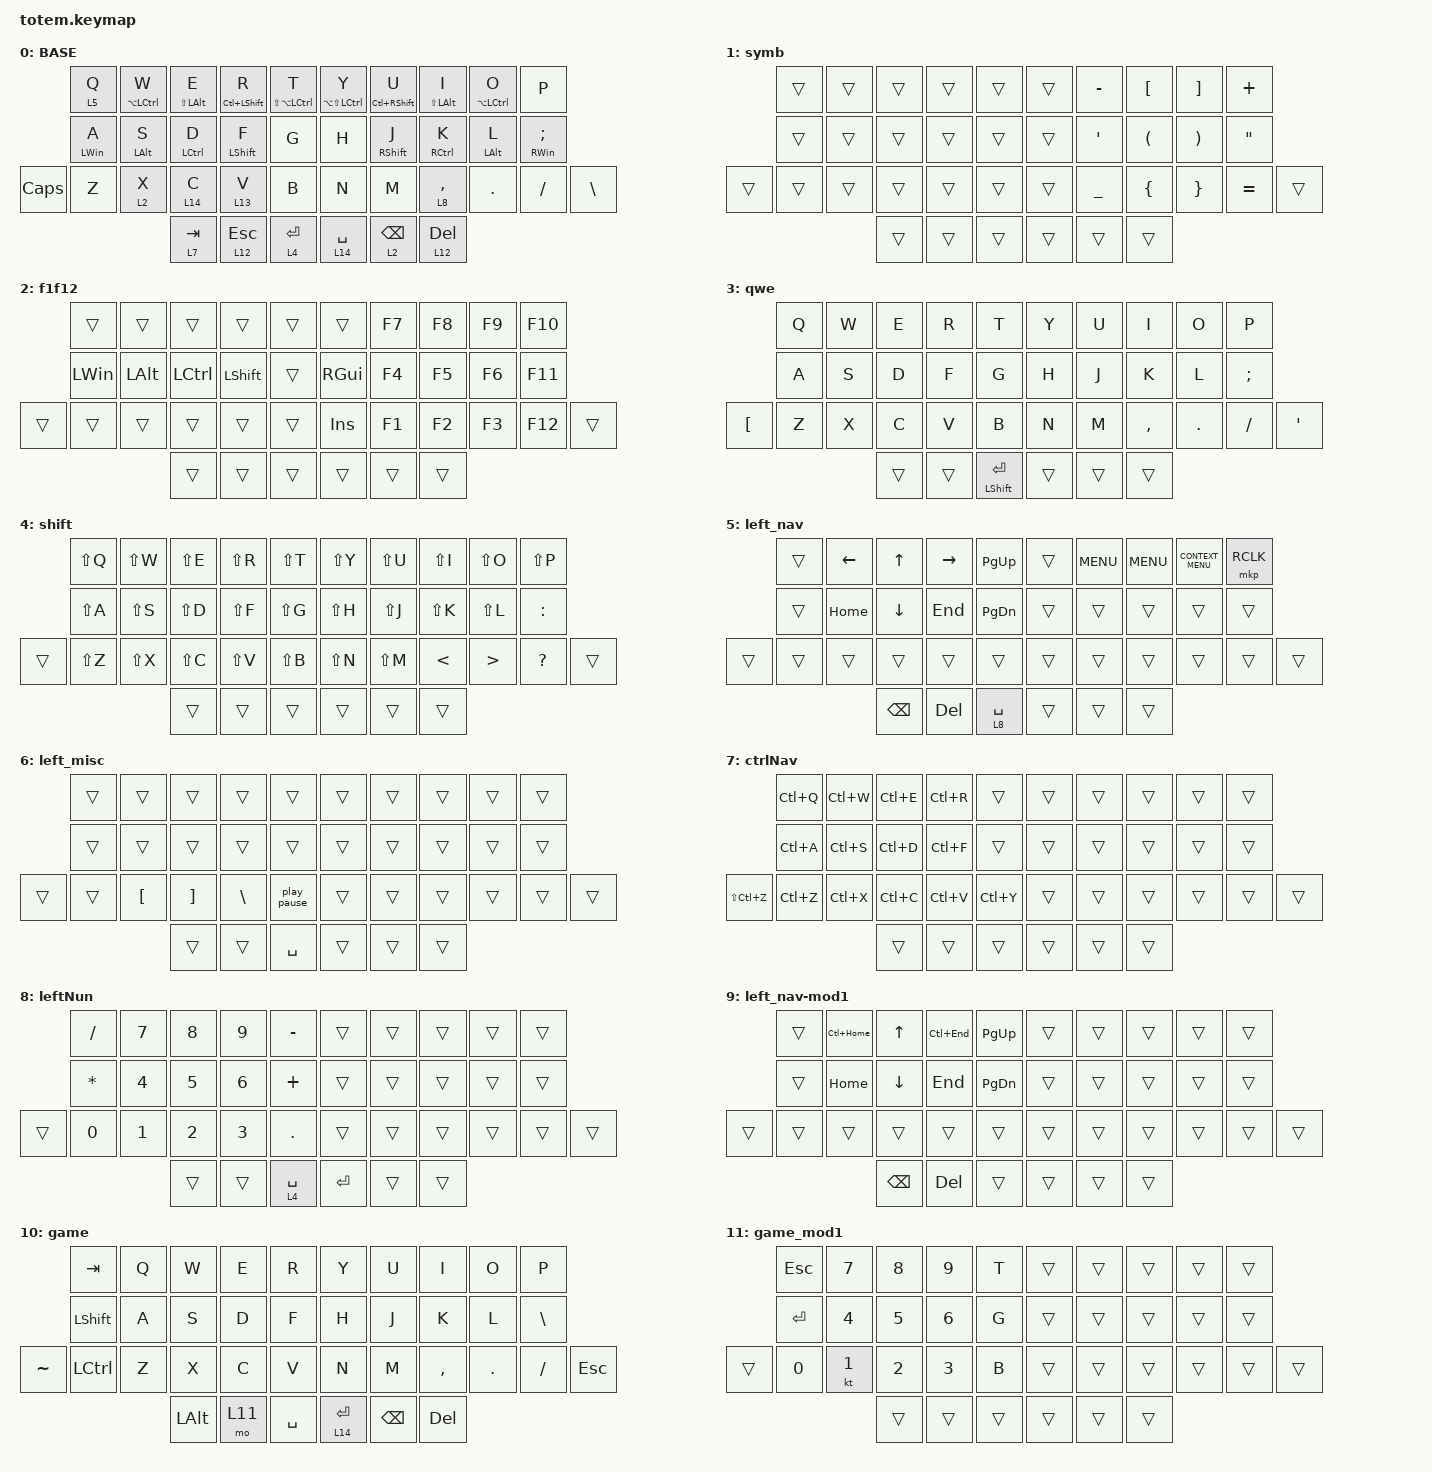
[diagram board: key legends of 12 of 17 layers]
//
//                                                        ▀▀▀▀▀     ▀▀▀▀▀          ▀▀█▀▀
//                                                        ▄▀▀▀▄  ▄  ▄▀▀▀▄  ▄  ▄▀▀▀▄  █  ▄▀▀▀▄
//                                                        █   █  █  █   █  █  █   █  █  █   █
//                                                         ▀▀▀   █   ▀▀▀   █   ▀▀▀   ▀   ▀▀▀
//                                                               █      ▄▄▄█▄▄▄    █   █  
//                                                               ▀      █  █  █     █▄█
//                                                             ▀▀▀▀▀    █  █  █      ▀
//                                                                      ▀  ▀  ▀
//
// ▄▄▄▄▄▄▄▄▄▄▄▄▄▄▄▄▄▄▄▄▄▄▄▄▄▄▄▄▄▄▄▄▄▄▄▄▄▄▄▄▄▄▄▄▄▄▄▄▄▄▄▄▄▄▄▄▄▄▄▄▄▄▄▄▄▄▄▄▄▄▄▄▄▄▄▄▄▄▄▄▄▄▄▄▄▄▄▄▄▄▄▄▄▄▄▄▄▄▄▄▄▄▄▄▄▄▄▄▄▄▄▄▄▄▄▄▄▄▄▄▄▄▄▄▄▄▄▄▄▄▄▄▄▄▄▄▄▄▄▄▄▄▄▄▄▄▄▄▄

#include <dt-bindings/zmk/mouse.h>
#include <behaviors.dtsi>
#include <dt-bindings/zmk/bt.h>
#include <dt-bindings/zmk/keys.h>
#include <dt-bindings/zmk/pointing.h>

#define BASE 0
#define NAV  1
#define SYM  2
#define ADJ  3
#define TVP1 4
#define TVP2 5

&mt {
    quick-tap-ms = <100>;
    global-quick-tap;
    flavor = "tap-preferred";
    tapping-term-ms = <170>;
};

/ {
    combos {
        compatible = "zmk,combos";

        rus {
            bindings = <&rus>;
            key-positions = <20 31>;
            layers = <0>;
            timeout-ms = <75>;
            require-prior-idle-ms = <200>;
        };

        eng {
            bindings = <&eng>;
            key-positions = <20 31>;
            layers = <3>;
            timeout-ms = <75>;
            require-prior-idle-ms = <200>;
        };

        LeftBracket {
            bindings = <&kp LEFT_BRACKET>;
            key-positions = <2 3>;
            layers = <0 4 3>;
            timeout-ms = <75>;
            require-prior-idle-ms = <75>;
        };

        RightBracket {
            bindings = <&kp RIGHT_BRACKET>;
            key-positions = <6 7>;
            layers = <0 4 3>;
            timeout-ms = <75>;
            require-prior-idle-ms = <75>;
        };

        LeftParenthesis {
            bindings = <&kp LEFT_PARENTHESIS>;
            key-positions = <12 13>;
            layers = <0 4 3>;
            timeout-ms = <75>;
            require-prior-idle-ms = <75>;
        };

        RightParenthesis {
            bindings = <&kp RIGHT_PARENTHESIS>;
            key-positions = <16 17>;
            layers = <0 4 3>;
            timeout-ms = <75>;
            require-prior-idle-ms = <75>;
        };

        LeftBrace {
            bindings = <&kp LEFT_BRACE>;
            key-positions = <23 24>;
            layers = <0 4 3>;
            timeout-ms = <75>;
            require-prior-idle-ms = <75>;
        };

        RightBrace {
            bindings = <&kp RIGHT_BRACE>;
            key-positions = <27 28>;
            layers = <0 4 3>;
            timeout-ms = <75>;
            require-prior-idle-ms = <75>;
        };

        Minus {
            bindings = <&kp MINUS>;
            key-positions = <1 2>;
            layers = <0 4 3>;
            timeout-ms = <75>;
            require-prior-idle-ms = <75>;
        };

        Plus {
            bindings = <&kp PLUS>;
            key-positions = <7 8>;
            layers = <0 4 3>;
            timeout-ms = <75>;
            require-prior-idle-ms = <75>;
        };

        Underscore {
            bindings = <&kp UNDER>;
            key-positions = <22 23>;
            layers = <0 4 3>;
            timeout-ms = <75>;
            require-prior-idle-ms = <75>;
        };

        Equal {
            bindings = <&kp EQUAL>;
            key-positions = <28 29>;
            layers = <0 4 3>;
            timeout-ms = <75>;
            require-prior-idle-ms = <75>;
        };

        Quote {
            bindings = <&kp EXCLAMATION>;
            key-positions = <16 18>;
            layers = <0 4 3>;
            timeout-ms = <75>;
            require-prior-idle-ms = <75>;
        };

        QuoteDouble {
            bindings = <&kp QUESTION>;
            key-positions = <13 11>;
            layers = <0 4 3>;
            timeout-ms = <75>;
            require-prior-idle-ms = <75>;
        };

        QuestionMark {
            bindings = <&kp QUESTION>;
            key-positions = <1 3>;
            layers = <0 4 3>;
            timeout-ms = <75>;
            require-prior-idle-ms = <75>;
        };

        Exclamation {
            bindings = <&kp EXCLAMATION>;
            key-positions = <6 8>;
            layers = <0 4 3>;
            timeout-ms = <75>;
            require-prior-idle-ms = <75>;
        };

        Percent {
            bindings = <&kp PERCENT>;
            key-positions = <22 24>;
            layers = <0 4 3>;
            timeout-ms = <75>;
            require-prior-idle-ms = <75>;
        };

        Asterisk {
            bindings = <&kp ASTERISK>;
            key-positions = <27 29>;
            layers = <0 4 3>;
            timeout-ms = <75>;
            require-prior-idle-ms = <75>;
        };

        Grave {
            bindings = <&kp GRAVE>;
            key-positions = <13 11 12>;
            layers = <0 4 3>;
            timeout-ms = <75>;
            require-prior-idle-ms = <75>;
        };

        Tilde {
            bindings = <&kp TILDE>;
            key-positions = <16 17 18>;
            layers = <0 4 3>;
            timeout-ms = <75>;
            require-prior-idle-ms = <75>;
        };

        AtSign {
            bindings = <&kp AT>;
            key-positions = <3 1 2>;
            layers = <0 4 3>;
            timeout-ms = <75>;
            require-prior-idle-ms = <75>;
        };

        Caret {
            bindings = <&kp CARET>;
            key-positions = <6 7 8>;
            layers = <0 4 3>;
            timeout-ms = <75>;
            require-prior-idle-ms = <75>;
        };

        Hash {
            bindings = <&kp HASH>;
            key-positions = <11 23>;
            layers = <0 4 3>;
            timeout-ms = <75>;
            require-prior-idle-ms = <75>;
        };

        Dollar {
            bindings = <&kp DOLLAR>;
            key-positions = <28 18>;
            layers = <0 4 3>;
            timeout-ms = <75>;
            require-prior-idle-ms = <75>;
        };

        Pipe {
            bindings = <&kp PIPE>;
            key-positions = <23 13>;
            layers = <0 4>;
            timeout-ms = <75>;
            require-prior-idle-ms = <75>;
        };

        Ampersand {
            bindings = <&kp AMPERSAND>;
            key-positions = <16 28>;
            layers = <0 4>;
            timeout-ms = <75>;
            require-prior-idle-ms = <75>;
        };

        Backslash2 {
            bindings = <&kp BACKSLASH>;
            key-positions = <1 12 13>;
            layers = <0 4 3>;
            timeout-ms = <75>;
            require-prior-idle-ms = <75>;
        };

        Backslash {
            bindings = <&kp SQT>;
            key-positions = <11 12>;
            layers = <0 4 3>;
            require-prior-idle-ms = <75>;
            timeout-ms = <75>;
        };

        Slash {
            bindings = <&kp DOUBLE_QUOTES>;
            key-positions = <17 18>;
            layers = <0 4 3>;
            require-prior-idle-ms = <75>;
            timeout-ms = <75>;
        };

        endDel {
            bindings = <&endDel>;
            key-positions = <21 22>;
            layers = <0 4>;
            timeout-ms = <75>;
            require-prior-idle-ms = <200>;
        };

        homeBackspace {
            bindings = <&homeBackspace>;
            key-positions = <30 29>;
            layers = <0 4>;
            timeout-ms = <75>;
            require-prior-idle-ms = <200>;
        };

        homeEndDel {
            bindings = <&homeEndDel>;
            key-positions = <11 12 17 18>;
            layers = <0>;
            timeout-ms = <75>;
            require-prior-idle-ms = <200>;
        };

        tab {
            bindings = <&kp TAB>;
            key-positions = <10 11>;
            layers = <0>;
            timeout-ms = <75>;
            require-prior-idle-ms = <200>;
        };

        caps {
            bindings = <&caps_word>;
            key-positions = <18 19>;
            layers = <0>;
            timeout-ms = <75>;
            require-prior-idle-ms = <200>;
        };

        bootloaderL {
            bindings = <&bootloader>;
            key-positions = <20 4>;
            timeout-ms = <75>;
            require-prior-idle-ms = <200>;
        };

        bootloaderR {
            bindings = <&bootloader>;
            key-positions = <31 5>;
            timeout-ms = <75>;
            require-prior-idle-ms = <200>;
        };

        releaseMods {
            bindings = <&release_mod>;
            key-positions = <2 7>;
            timeout-ms = <75>;
            require-prior-idle-ms = <200>;
        };

        toggleNav {
            bindings = <&tog 14>;
            key-positions = <35 17>;
            layers = <0 14>;
            timeout-ms = <75>;
            require-prior-idle-ms = <200>;
        };

        toggleNum {
            bindings = <&tog 13>;
            key-positions = <35 16>;
            layers = <0 13>;
            timeout-ms = <75>;
            require-prior-idle-ms = <200>;
        };

        game {
            bindings = <&tog 10>;
            key-positions = <0 9>;
        };

        btclr {
            bindings = <&bt BT_CLR>;
            key-positions = <23 20 2>;
        };

        sys-reset {
            bindings = <&sys_reset>;
            key-positions = <20 2 34>;
        };
    };

    macros {
        gif: gif {
            label = "giphy";
            compatible = "zmk,behavior-macro";
            #binding-cells = <0>;
            bindings =
                <&macro_press>,
                <&kp LSHFT>,
                <&macro_tap>,
                <&kp N2>,
                <&macro_release>,
                <&kp LSHFT>,
                <&macro_tap>,
                <&kp G &kp I &kp F>;
        };

        rus: rus {
            compatible = "zmk,behavior-macro";
            #binding-cells = <0>;
            bindings = <&kp LA(LC(SPACE)) &tog 3>;
            label = "RUS";
        };

        eng: eng {
            compatible = "zmk,behavior-macro";
            #binding-cells = <0>;
            bindings = <&kp LA(LC(SPACE)) &tog 3>;
            label = "ENG";
        };

        ctrlBackspace: ctrlDel {
            compatible = "zmk,behavior-macro";
            #binding-cells = <0>;
            bindings = <&kp LC(BACKSPACE)>;
            label = "CTRLDEL";
        };

        homeBackspace: homeBackspace {
            compatible = "zmk,behavior-macro";
            #binding-cells = <0>;
            bindings =
                <&macro_press>,
                <&kp LEFT_SHIFT>,
                <&macro_tap>,
                <&kp HOME>,
                <&macro_release>,
                <&kp LEFT_SHIFT>,
                <&macro_tap>,
                <&kp DELETE>;

            label = "HOMEBACKSPACE";
        };

        endDel: endDel {
            compatible = "zmk,behavior-macro";
            #binding-cells = <0>;
            bindings =
                <&macro_press>,
                <&kp LEFT_SHIFT>,
                <&macro_tap>,
                <&kp END>,
                <&macro_release>,
                <&kp LEFT_SHIFT>,
                <&macro_tap>,
                <&kp DELETE>;

            label = "ENDDEL";
        };

        homeEndDel: homeEndDel {
            compatible = "zmk,behavior-macro";
            #binding-cells = <0>;
            bindings =
                <&macro_tap>,
                <&kp HOME>,
                <&macro_press>,
                <&kp LEFT_SHIFT>,
                <&macro_tap>,
                <&kp END>,
                <&macro_release>,
                <&kp LEFT_SHIFT>,
                <&macro_tap>,
                <&kp DELETE>;

            label = "HOMEENDDEL";
        };

        ctrlDel2: ctrlDel2 {
            compatible = "zmk,behavior-macro";
            #binding-cells = <0>;
            bindings = <&kp LC(DELETE)>;
            label = "CTRLDEL2";
        };

        play_pause: play_pause {
            compatible = "zmk,behavior-macro";
            #binding-cells = <0>;
            bindings = <&kp LC(LS(KP_SUBTRACT))>;
            label = "PLAY_PAUSE";
        };

        toggle_toggl: toggle_toggl {
            compatible = "zmk,behavior-macro";
            #binding-cells = <0>;
            bindings = <&kp RC(KP_NUMBER_0)>;
            label = "TOGGLE_TOGGL";
        };

        release_mod: release_mod {
            compatible = "zmk,behavior-macro";
            #binding-cells = <0>;
            bindings =
                <&macro_release>,
                <&kp LEFT_SHIFT &kp RIGHT_SHIFT &kp LEFT_CONTROL &kp RIGHT_CONTROL &kp LEFT_ALT &kp RIGHT_ALT &kp LEFT_WIN &kp RIGHT_WIN>,
                <&macro_tap>,
                <&to 0>,
                <&macro_tap>,
                <&sys_reset>;

            label = "RELEASE_MOD";
        };
    };

    behaviors {
        hmr: hmr {
            compatible = "zmk,behavior-hold-tap";
            label = "HMR";
            bindings = <&kp>, <&kp>;

            #binding-cells = <2>;
            hold-trigger-key-positions = <0 1 2 3 4 10 11 12 13 14 20 21 22 23 24 25 32 33 34 35 36 37>;
            flavor = "balanced";
            hold-trigger-on-release;
            tapping-term-ms = <280>;
            quick-tap-ms = <175>;
        };

        hml: hml {
            compatible = "zmk,behavior-hold-tap";
            label = "HML";
            bindings = <&kp>, <&kp>;

            #binding-cells = <2>;
            tapping-term-ms = <280>;
            quick-tap-ms = <175>;
            flavor = "balanced";
            hold-trigger-on-release;
            hold-trigger-key-positions = <5 6 7 8 9 15 16 17 18 19 26 27 28 29 30 31 35 36 37 32 33 34>;
        };

        enter_shift: enter_shift {
            compatible = "zmk,behavior-hold-tap";
            label = "ENTER_SHIFT";
            bindings = <&kp>, <&kp>;

            #binding-cells = <2>;
            tapping-term-ms = <280>;
            quick-tap-ms = <175>;
            hold-trigger-on-release;
            hold-trigger-key-positions = <5 6 7 8 9 15 16 17 18 19 26 27 28 29 30 31 0 1 2 3 4 10 11 12 13 14 20 21 22 23 24 25>;
        };

        hml_layer: hml_layer {
            compatible = "zmk,behavior-hold-tap";
            label = "HML_LAYER";
            bindings = <&lt>, <&kp>;

            #binding-cells = <2>;
            tapping-term-ms = <280>;
            quick-tap-ms = <175>;
            flavor = "balanced";
            hold-trigger-on-release;
            hold-trigger-key-positions = <5 6 7 8 9 15 16 17 18 19 26 27 28 29 30 31 35 36 37 32 33 34>;
        };

        bal_nav: bal_nav {
            compatible = "zmk,behavior-hold-tap";
            label = "BAL_NAV";
            bindings = <&mo>, <&kp>;

            #binding-cells = <2>;
            flavor = "balanced";
            tapping-term-ms = <280>;
            quick-tap-ms = <175>;
            hold-trigger-key-positions = <5 6 7 8 9 15 16 17 18 19 26 27 28 29 30 31 13 12 11 10 0 1 2 3 4 10 11 12 13 14 22 25 20 21 23 24 32 33 34 35 36 37>;
            hold-trigger-on-release;
        };

        hold_nav: hold_nav {
            compatible = "zmk,behavior-hold-tap";
            label = "HOLD_NAV";
            bindings = <&mo>, <&kp>;

            #binding-cells = <2>;
            tapping-term-ms = <280>;
            quick-tap-ms = <150>;
            hold-trigger-key-positions = <5 6 8 9 15 16 17 18 19 26 27 28 29 30 31 7 2 20 21 0 1 2 3 4 10 11 12 13 14 20 21 22 23 24 25>;
            hold-trigger-on-release;
        };

        hml_hold: hml_hold {
            compatible = "zmk,behavior-hold-tap";
            label = "HML_HOLD";
            bindings = <&kp>, <&kp>;

            #binding-cells = <2>;
            tapping-term-ms = <280>;
            quick-tap-ms = <175>;
            flavor = "balanced";
            hold-trigger-on-release;
            hold-trigger-key-positions = <5 6 7 8 9 15 16 17 18 19 26 27 28 29 30 31 35 36 37 32 33 34>;
            hold-while-undecided;
        };
    };

    keymap {
        compatible = "zmk,keymap";

        // ▄▄▄▄▄▄▄▄▄▄▄▄▄▄▄▄▄▄▄▄▄▄▄▄▄▄▄▄▄▄▄▄▄▄▄▄▄▄▄▄▄▄▄▄▄▄▄▄▄▄▄▄▄▄▄▄▄▄▄▄▄▄▄▄▄▄▄▄▄▄▄▄▄▄▄▄▄▄▄▄▄▄▄▄▄▄▄▄▄▄▄▄▄▄▄▄▄▄▄▄▄▄▄▄▄▄▄▄▄▄▄▄▄▄▄▄▄▄▄▄▄▄▄▄▄▄▄▄▄▄▄▄▄▄▄▄▄▄▄▄▄▄▄▄▄▄▄▄▄

        base_layer {
            // ┏━━━━━━━━━━━━━━━━━━━━━━━━━━━━━━━━━━━━━━━┓

            label = "BASE";

            // ┗━━━━━━━━━━━━━━━━━━━━━━━━━━━━━━━━━━━━━━━┛
            //             ┏━━━━━━━━━━━┳━━━━━━━━━━━┳━━━━━━━━━━━┳━━━━━━━━━━━┳━━━━━━━━━━━┓   ┏━━━━━━━━━━━┳━━━━━━━━━━━┳━━━━━━━━━━━┳━━━━━━━━━━━┳━━━━━━━━━━━┓
            //             ┃     Q     ┃     W     ┃     F     ┃     P     ┃     G     ┃   ┃     J     ┃     L     ┃     U     ┃     Y     ┃     ;     ┃
            //             ┣━━━━━━━━━━━╋━━━━━━━━━━━╋━━━━━━━━━━━╋━━━━━━━━━━━╋━━━━━━━━━━━┫   ┣━━━━━━━━━━━╋━━━━━━━━━━━╋━━━━━━━━━━━╋━━━━━━━━━━━╋━━━━━━━━━━━┫
            //             ┃     A     ┃     R     ┃     S     ┃     T     ┃     D     ┃   ┃     H     ┃     N     ┃     E     ┃     I     ┃     O     ┃
            // ┏━━━━━━━━━━━╋━━━━━━━━━━━╋━━━━━━━━━━━╋━━━━━━━━━━━╋━━━━━━━━━━━╋━━━━━━━━━━━┫   ┣━━━━━━━━━━━╋━━━━━━━━━━━╋━━━━━━━━━━━╋━━━━━━━━━━━╋━━━━━━━━━━━╋━━━━━━━━━━━┓
            // ┃     Q     ┃     Z     ┃     X     ┃     C     ┃     V     ┃     B     ┃   ┃     K     ┃     M     ┃     ,     ┃     .     ┃     /     ┃     \     ┃
            // ┗━━━━━━━━━━━┻━━━━━━━━━━━┻━━━━━━━━━━━╋━━━━━━━━━━━╋━━━━━━━━━━━╋━━━━━━━━━━━┫   ┣━━━━━━━━━━━╋━━━━━━━━━━━╋━━━━━━━━━━━╋━━━━━━━━━━━┻━━━━━━━━━━━┻━━━━━━━━━━━┛
            //                                     ┃    DEL    ┃    TAB    ┃    SPC    ┃   ┃   ENTER   ┃           ┃   BSPC    ┃
            //                                     ┗━━━━━━━━━━━┻━━━━━━━━━━━┻━━━━━━━━━━━┛   ┗━━━━━━━━━━━┻━━━━━━━━━━━┻━━━━━━━━━━━┛

            bindings = <
              &bal_nav 5 Q     &hml LA(LCTRL) W  &hml LS(LEFT_ALT) E       &hml LC(LEFT_SHIFT) R   &hml LS(LA(LCTRL)) T    &hmr LA(LS(LEFT_CONTROL)) Y  &hmr LC(RIGHT_SHIFT) U  &hmr LS(LEFT_ALT) I   &hmr LA(LEFT_CONTROL) O  &kp P
              &hml LEFT_WIN A  &hml LEFT_ALT S   &hml_hold LEFT_CONTROL D  &hml_hold LEFT_SHIFT F  &kp G                   &kp H                        &hmr RIGHT_SHIFT J      &hmr RIGHT_CONTROL K  &hmr LEFT_ALT L          &hmr RIGHT_WIN SEMICOLON
&kp CAPSLOCK  &kp Z            &bal_nav 2 X      &bal_nav 14 C             &bal_nav 13 V           &kp B                   &kp N                        &kp M                   &bal_nav 8 COMMA      &kp DOT                  &kp FSLH                  &kp BSLH
                                                 &hold_nav 7 TAB           &hold_nav 12 ESCAPE     &hold_nav 4 ENTER       &bal_nav 14 SPACE            &lt 2 BACKSPACE         &lt 12 DEL
            >;
        };

        symbols {
            bindings = <
        &trans  &trans  &trans  &trans  &trans    &trans  &kp MINUS       &kp LEFT_BRACKET      &kp RIGHT_BRACKET      &kp PLUS
        &trans  &trans  &trans  &trans  &trans    &trans  &kp SQT         &kp LEFT_PARENTHESIS  &kp RIGHT_PARENTHESIS  &kp DOUBLE_QUOTES
&trans  &trans  &trans  &trans  &trans  &trans    &trans  &kp UNDERSCORE  &kp LEFT_BRACE        &kp RIGHT_BRACE        &kp EQUAL          &trans
                        &trans  &trans  &trans    &trans  &trans          &trans
            >;

            label = "symb";
        };

        F1_F12 {
            bindings = <
        &trans        &trans        &trans     &trans          &trans    &trans         &kp F7  &kp F8  &kp F9  &kp F10
        &kp LEFT_WIN  &kp LEFT_ALT  &kp LCTRL  &kp LEFT_SHIFT  &trans    &kp RIGHT_GUI  &kp F4  &kp F5  &kp F6  &kp F11
&trans  &trans        &trans        &trans     &trans          &trans    &kp INSERT     &kp F1  &kp F2  &kp F3  &kp F12  &trans
                                    &trans     &trans          &trans    &trans         &trans  &trans
            >;

            label = "f1f12";
        };

        qwerty {
            bindings = <
                  &kp Q  &kp W  &kp E   &kp R   &kp T                   &kp Y   &kp U   &kp I      &kp O       &kp P
                  &kp A  &kp S  &kp D   &kp F   &kp G                   &kp H   &kp J   &kp K      &kp L       &kp SEMICOLON
&kp LEFT_BRACKET  &kp Z  &kp X  &kp C   &kp V   &kp B                   &kp N   &kp M   &kp COMMA  &kp PERIOD  &kp SLASH      &kp SQT
                                &trans  &trans  &mt LEFT_SHIFT ENTER    &trans  &trans  &trans
            >;

            label = "qwe";
        };

        shift {
            bindings = <
        &kp LS(Q)  &kp LS(W)  &kp LS(E)  &kp LS(R)  &kp LS(T)    &kp LS(Y)  &kp LS(U)  &kp LS(I)      &kp LS(O)         &kp LS(P)
        &kp LS(A)  &kp LS(S)  &kp LS(D)  &kp LS(F)  &kp LS(G)    &kp LS(H)  &kp LS(J)  &kp LS(K)      &kp LS(L)         &kp COLON
&trans  &kp LS(Z)  &kp LS(X)  &kp LS(C)  &kp LS(V)  &kp LS(B)    &kp LS(N)  &kp LS(M)  &kp LESS_THAN  &kp GREATER_THAN  &kp QUESTION  &trans
                              &trans     &trans     &trans       &trans     &trans     &trans
            >;

            label = "shift";
        };

        left_nav {
            bindings = <
        &trans  &kp LEFT  &kp UP_ARROW   &kp RIGHT   &kp PAGE_UP          &trans  &kp C_MENU  &kp K_MENU  &kp K_CONTEXT_MENU  &mkp RCLK
        &trans  &kp HOME  &kp DOWN       &kp END     &kp PAGE_DOWN        &trans  &trans      &trans      &trans              &trans
&trans  &trans  &trans    &trans         &trans      &trans               &trans  &trans      &trans      &trans              &trans     &trans
                          &kp BACKSPACE  &kp DELETE  &hold_nav 8 SPACE    &trans  &trans      &trans
            >;

            label = "left_nav";
        };

        left_misc {
            bindings = <
        &trans  &trans            &trans             &trans         &trans         &trans  &trans  &trans  &trans  &trans
        &trans  &trans            &trans             &trans         &trans         &trans  &trans  &trans  &trans  &trans
&trans  &trans  &kp LEFT_BRACKET  &kp RIGHT_BRACKET  &kp BACKSLASH  &play_pause    &trans  &trans  &trans  &trans  &trans  &trans
                                  &trans             &trans         &kp SPACE      &trans  &trans  &trans
            >;

            label = "left_misc";
        };

        ctrl_nav {
            bindings = <
               &kp LC(Q)  &kp LC(W)  &kp LC(E)  &kp LC(R)  &trans       &trans  &trans  &trans  &trans  &trans
               &kp LC(A)  &kp LC(S)  &kp LC(D)  &kp LC(F)  &trans       &trans  &trans  &trans  &trans  &trans
&kp LS(LC(Z))  &kp LC(Z)  &kp LC(X)  &kp LC(C)  &kp LC(V)  &kp LC(Y)    &trans  &trans  &trans  &trans  &trans  &trans
                                     &trans     &trans     &trans       &trans  &trans  &trans
            >;

            label = "ctrlNav";
        };

        left_num {
            bindings = <
        &kp SLASH     &kp N7        &kp N8        &kp N9        &kp MINUS            &trans     &trans  &trans  &trans  &trans
        &kp ASTERISK  &kp NUMBER_4  &kp N5        &kp NUMBER_6  &kp PLUS             &trans     &trans  &trans  &trans  &trans
&trans  &kp NUMBER_0  &kp NUMBER_1  &kp NUMBER_2  &kp NUMBER_3  &kp PERIOD           &trans     &trans  &trans  &trans  &trans  &trans
                                    &trans        &trans        &hold_nav 4 SPACE    &kp ENTER  &trans  &trans
            >;

            label = "leftNun";
        };

        left_nav-mod1 {
            label = "left_nav-mod1";
            bindings = <
        &trans  &kp LC(HOME)  &kp UP_ARROW   &kp LC(END)  &kp PAGE_UP      &trans  &trans  &trans  &trans  &trans
        &trans  &kp HOME      &kp DOWN       &kp END      &kp PAGE_DOWN    &trans  &trans  &trans  &trans  &trans
&trans  &trans  &trans        &trans         &trans       &trans           &trans  &trans  &trans  &trans  &trans  &trans
                              &kp BACKSPACE  &kp DELETE   &trans           &trans  &trans  &trans
            >;
        };

        game {
            bindings = <
           &kp TAB         &kp Q  &kp W         &kp E   &kp R        &kp Y         &kp U          &kp I       &kp O       &kp P
           &kp LEFT_SHIFT  &kp A  &kp S         &kp D   &kp F        &kp H         &kp J          &kp K       &kp L       &kp BACKSLASH
&kp TILDE  &kp LCTRL       &kp Z  &kp X         &kp C   &kp V        &kp N         &kp M          &kp COMMA   &kp PERIOD  &kp SLASH      &kp ESCAPE
                                  &kp LEFT_ALT  &mo 11  &kp SPACE    &lt 14 ENTER  &kp BACKSPACE  &kp DELETE
            >;

            label = "game";
        };

        game_mod1 {
            bindings = <
        &kp ESCAPE    &kp NUMBER_7  &kp NUMBER_8  &kp NUMBER_9  &kp T     &trans  &trans  &trans  &trans  &trans
        &kp ENTER     &kp NUMBER_4  &kp NUMBER_5  &kp NUMBER_6  &kp G     &trans  &trans  &trans  &trans  &trans
&trans  &kp NUMBER_0  &kt NUMBER_1  &kp NUMBER_2  &kp NUMBER_3  &kp B     &trans  &trans  &trans  &trans  &trans  &trans
                                    &trans        &trans        &trans    &trans  &trans  &trans
            >;

            label = "game_mod1";
        };

        numbers {
            // ┏━━━━━━━━━━━━━━━━━━━━━━━━━━━━━━━━━━━━━━━┓

            label = "num";

            // ┗━━━━━━━━━━━━━━━━━━━━━━━━━━━━━━━━━━━━━━━┛
            //             ┏━━━━━━━━━━━┳━━━━━━━━━━━┳━━━━━━━━━━━┳━━━━━━━━━━━┳━━━━━━━━━━━┓   ┏━━━━━━━━━━━┳━━━━━━━━━━━┳━━━━━━━━━━━┳━━━━━━━━━━━┳━━━━━━━━━━━┓
            //             ┃           ┃           ┃     UP    ┃           ┃     {     ┃   ┃     }     ┃     7     ┃     8     ┃     9     ┃     +     ┃
            //             ┣━━━━━━━━━━━╋━━━━━━━━━━━╋━━━━━━━━━━━╋━━━━━━━━━━━╋━━━━━━━━━━━┫   ┣━━━━━━━━━━━╋━━━━━━━━━━━╋━━━━━━━━━━━╋━━━━━━━━━━━╋━━━━━━━━━━━┫
            //             ┃   SHIFT   ┃   LEFT    ┃    DOWN   ┃   RIGHT   ┃     [     ┃   ┃     ]     ┃     4     ┃     5     ┃     6     ┃     -     ┃
            // ┏━━━━━━━━━━━╋━━━━━━━━━━━╋━━━━━━━━━━━╋━━━━━━━━━━━╋━━━━━━━━━━━╋━━━━━━━━━━━┫   ┣━━━━━━━━━━━╋━━━━━━━━━━━╋━━━━━━━━━━━╋━━━━━━━━━━━╋━━━━━━━━━━━╋━━━━━━━━━━━┓
            // ┃           ┃           ┃   P UP    ┃  C LOCK   ┃  P DOWN   ┃     (     ┃   ┃     )     ┃     1     ┃     2     ┃     3     ┃     *     ┃           ┃
            // ┗━━━━━━━━━━━┻━━━━━━━━━━━┻━━━━━━━━━━━╋━━━━━━━━━━━╋━━━━━━━━━━━╋━━━━━━━━━━━┫   ┣━━━━━━━━━━━╋━━━━━━━━━━━╋━━━━━━━━━━━╋━━━━━━━━━━━┻━━━━━━━━━━━┻━━━━━━━━━━━┛
            //                                     ┃           ┃    TAB    ┃    SPC    ┃   ┃    DEL    ┃     0     ┃           ┃
            //                                     ┗━━━━━━━━━━━┻━━━━━━━━━━━┻━━━━━━━━━━━┛   ┗━━━━━━━━━━━┻━━━━━━━━━━━┻━━━━━━━━━━━┛

            bindings = <
               &trans        &trans        &kp PERIOD        &kp AMPERSAND   &trans           &kp KP_DIVIDE    &kp N7        &kp N8        &kp N9        &kp KP_SUBTRACT
               &kp LEFT_WIN  &kp LEFT_ALT  &kp LEFT_CONTROL  &kp LEFT_SHIFT  &toggle_toggl    &kp KP_MULTIPLY  &kp NUMBER_4  &kp N5        &kp NUMBER_6  &kp KP_PLUS
&kp LS(LC(Z))  &kp LC(Z)     &kp LC(X)     &kp LC(C)         &kp LC(V)       &kp LC(Y)        &kp INSERT       &kp NUMBER_1  &kp NUMBER_2  &kp NUMBER_3  &kp BACKSLASH    &kp N0
                                           &trans            &trans          &trans           &kp NUMBER_0     &trans        &trans
            >;
        };

        numbers-pinky {
            label = "num-pin";
            bindings = <
        &trans        &trans            &trans             &trans          &trans               &kp KP_DIVIDE    &kp N7        &kp N8        &kp N9        &kp KP_SUBTRACT
        &kp LEFT_WIN  &kp LEFT_ALT      &kp LEFT_CONTROL   &kp LEFT_SHIFT  &trans               &kp KP_MULTIPLY  &kp NUMBER_4  &kp N5        &kp NUMBER_6  &kp KP_PLUS
&trans  &kp LC(Z)     &kp LEFT_BRACKET  &kp RIGHT_BRACKET  &kp BACKSLASH   &trans               &kp INSERT       &kp NUMBER_1  &kp NUMBER_2  &kp NUMBER_3  &kp PERIOD       &trans
                                        &kp LEFT           &kp RIGHT       &bal_nav 14 SPACE    &kp NUMBER_0     &trans        &trans
            >;
        };

        nav {
            bindings = <
        &trans  &trans  &trans            &trans          &trans    &kp C_VOLUME_UP  &play_pause     &kp K_APP       &kp PRINTSCREEN  &kp LS(CAPSLOCK)
        &trans  &trans  &kp LEFT_CONTROL  &kp LEFT_SHIFT  &trans    &kp C_VOL_DN     &kp LEFT_ARROW  &kp DOWN_ARROW  &kp UP_ARROW     &kp RIGHT
&trans  &trans  &trans  &trans            &trans          &trans    &kp C_MUTE       &kp HOME        &kp PAGE_DOWN   &kp PAGE_UP      &kp END           &trans
                        &trans            &trans          &trans    &trans           &trans          &trans
            >;

            label = "nav";
        };

        nav_mod1 {
            bindings = <
        &trans  &trans  &trans  &trans  &trans    &trans  &kp LS(LC(LEFT_BRACKET))  &trans  &kp LS(LC(RIGHT_BRACKET))  &trans
        &trans  &trans  &trans  &trans  &trans    &trans  &trans                    &trans  &trans                     &trans
&trans  &trans  &trans  &trans  &trans  &trans    &trans  &trans                    &trans  &trans                     &trans  &trans
                        &trans  &trans  &trans    &trans  &trans                    &trans
            >;

            label = "nav_mod1";
        };

        colemak-0 {
            label = "old";
            bindings = <
              &bal_nav 5 Q     &hml LA(LCTRL) W  &hml LS(LEFT_ALT) F       &hml LC(LEFT_SHIFT) P   &hml LS(LA(LCTRL)) B    &hmr LA(LS(LEFT_CONTROL)) J  &hmr LC(RIGHT_SHIFT) L  &hmr LS(LEFT_ALT) U   &hmr LA(LEFT_CONTROL) Y  &kp SEMICOLON
              &hml LEFT_WIN A  &hml LEFT_ALT R   &hml_hold LEFT_CONTROL S  &hml_hold LEFT_SHIFT T  &kp G                   &kp M                        &hmr RIGHT_SHIFT N      &hmr RIGHT_CONTROL E  &hmr LEFT_ALT I          &hmr RIGHT_WIN O
&kp CAPSLOCK  &kp Z            &bal_nav 2 X      &bal_nav 14 C             &bal_nav 13 D           &kp V                   &kp K                        &kp H                   &bal_nav 8 COMMA      &kp DOT                  &kp FSLH          &kp BSLH
                                                 &hold_nav 7 TAB           &hold_nav 12 ESCAPE     &hold_nav 4 ENTER       &bal_nav 14 SPACE            &lt 2 BACKSPACE         &lt 12 DEL
            >;
        };
    };
};
